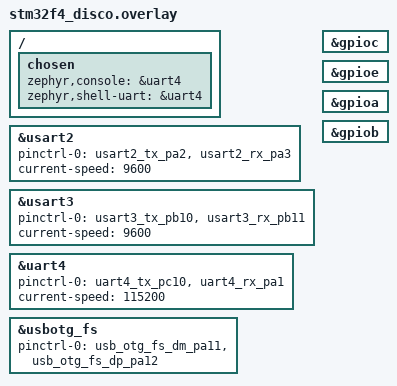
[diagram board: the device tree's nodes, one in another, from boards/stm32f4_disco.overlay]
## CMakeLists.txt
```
cmake_minimum_required(VERSION 3.20.0)

find_package(Zephyr REQUIRED HINTS $ENV{ZEPHYR_BASE})
project(usb_hid_proxy)

# Add source files
target_sources(app PRIVATE
    src/main.c
    src/drivers/ch375.c
    src/drivers/ch375_host.c
    src/drivers/ch375_uart.c
    src/hid/hid_parser.c
    src/hid/hid_mouse.c
    src/hid/hid_keyboard.c
    src/usb/composite_hid.c
    src/auto_gun_press.c
)

# Add include directories
target_include_directories(app PRIVATE
    ${CMAKE_CURRENT_SOURCE_DIR}/include
)

# Link against STM32 LL libraries for direct UART access
# These are needed for 9-bit UART configuration
zephyr_library_include_directories(
    ${ZEPHYR_BASE}/modules/hal/stm32/stm32cube/stm32f4xx/drivers/include
    ${ZEPHYR_BASE}/modules/hal/stm32/stm32cube/stm32f4xx/soc
)
```

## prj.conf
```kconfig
CONFIG_CONSOLE=y
CONFIG_UART_CONSOLE=y
CONFIG_GPIO=y
CONFIG_LOG=y
CONFIG_LOG_DEFAULT_LEVEL=3
```

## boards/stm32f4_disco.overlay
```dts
/ {
    chosen {
        zephyr,console = &uart4;
        zephyr,shell-uart = &uart4;
    };
};

/* Configure UARTs for CH375 */
&usart2 {
    pinctrl-0 = <&usart2_tx_pa2 &usart2_rx_pa3>;
    pinctrl-names = "default";
    current-speed = <9600>;
    status = "okay";
};

&usart3 {
    pinctrl-0 = <&usart3_tx_pb10 &usart3_rx_pb11>;
    pinctrl-names = "default";
    current-speed = <9600>;
    status = "okay";
};

/* Log UART */
&uart4 {
    pinctrl-0 = <&uart4_tx_pc10 &uart4_rx_pa1>;
    pinctrl-names = "default";
    current-speed = <115200>;
    status = "okay";
};

/* USB OTG FS for device mode */
&usbotg_fs {
    status = "okay";
    pinctrl-0 = <&usb_otg_fs_dm_pa11 &usb_otg_fs_dp_pa12>;
    pinctrl-names = "default";
};

/* GPIO ports */
&gpioc {
    status = "okay";
};

&gpioe {
    status = "okay";
};

&gpioa {
    status = "okay";
};

&gpiob {
    status = "okay";
};
```

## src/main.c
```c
/* Main application - Zephyr style with proper device tree usage */

#include <zephyr/kernel.h>
#include <zephyr/device.h>
#include <zephyr/drivers/gpio.h>
#include <zephyr/drivers/uart.h>
#include <zephyr/usb/usb_device.h>
#include <zephyr/usb/class/usb_hid.h>
#include <zephyr/logging/log.h>

#include "ch375/ch375.h"
#include "ch375/ch375_host.h"
#include "ch375/ch375_uart.h"
#include "hid/hid_mouse.h"
#include "hid/hid_keyboard.h"
#include "usb/composite_hid.h"
#include "auto_gun_press.h"

LOG_MODULE_REGISTER(main, LOG_LEVEL_INF);

#define CH375_MODULE_NUM 2

/* Device context structure */
typedef struct {
    const char *name;
    const struct device *uart_dev;
    struct gpio_dt_spec int_gpio;

    struct ch375_context *ch375_ctx;
    struct usb_device usbdev;
    struct usbhid_device hiddev;
    union {
        struct hid_mouse mouse;
        struct hid_keyboard keyboard;
    };

    uint8_t is_connected;
    uint8_t interface_num;
} device_input_t;

/* Global state */
static device_input_t s_arr_devin[CH375_MODULE_NUM];
static struct agp_context *s_agp_ctx;
static uint8_t s_enable_gun_press;
static uint8_t s_started_gun_press;

/* Forward declaration for composite HID send function (provided by your composite_hid module) */
int composite_hid_send_report(uint8_t iface_index, const uint8_t *report, size_t len);

/* Device initialization using device tree */
static int init_device_input_dt(device_input_t *devin,
                                const char *uart_label,
                                const struct device *uart_dev,
                                const struct gpio_dt_spec *int_gpio,
                                const char *dev_name,
                                uint8_t interface_num)
{
    int ret;

    devin->name = dev_name;
    devin->interface_num = interface_num;
    devin->int_gpio = *int_gpio;
    devin->uart_dev = uart_dev;

    if (!device_is_ready(devin->uart_dev)) {
        LOG_ERR("UART device %s not ready", uart_label);
        return -ENODEV;
    }

    LOG_INF("Found UART device: %s", uart_label);

    /* Initialize CH375 hardware */
    ret = ch375_hw_init(devin->name,
                       devin->uart_dev,
                       devin->int_gpio,
                       CH375_DEFAULT_BAUDRATE,
                       &devin->ch375_ctx);
    if (ret < 0) {
        LOG_ERR("Failed to init CH375 hardware: %d", ret);
        return ret;
    }

    /* Initialize CH375 in host mode */
    ret = ch375_host_init(devin->ch375_ctx, CH375_WORK_BAUDRATE);
    if (ret != CH375_HOST_SUCCESS) {
        LOG_ERR("Failed to initialize CH375 host: %d", ret);
        return -EIO;
    }

    /* Reconfigure UART for working baudrate */
    ret = ch375_hw_set_baudrate(devin->ch375_ctx, CH375_WORK_BAUDRATE);
    if (ret < 0) {
        LOG_ERR("Failed to set working baudrate: %d", ret);
        return ret;
    }

    LOG_INF("Initialized %s", devin->name);
    return 0;
}

/* Process mouse HID reports */
static int handle_mouse(struct hid_mouse *mouse, uint8_t interface_num)
{
    struct usbhid_device *hiddev = mouse->hid_dev;
    uint8_t *report_buf = NULL;
    int ret;
    uint32_t button_value;
    uint8_t fetch_success = 0;
    uint8_t need_send = 0;
    size_t report_len = hiddev->report_length;

    /* Fetch incoming report from host-side device. This updates the usbhid report buffer. */
    ret = hid_mouse_fetch_report(mouse);
    if (ret == USBHID_SUCCESS) {
        fetch_success = 1;
        need_send = 1;
    }

    /* Grab pointer to the report buffer (may be internal) */
    ret = usbhid_get_report_buffer(hiddev, &report_buf, NULL, USBHID_NOW);
    if (ret != USBHID_SUCCESS) {
        /* If no new report and nothing to send, skip */
        if (!need_send) {
            return 0;
        }
        /* fallback: still try to proceed if report_buf NULL */
    }

    /* Check left mouse button for auto gun press */
    hid_mouse_get_button(mouse, HID_MOUSE_BUTTON_LEFT, &button_value, USBHID_NOW);
    if (button_value) {
        if (!s_started_gun_press) {
            s_started_gun_press = 1;
            agp_restart(s_agp_ctx);
        }
    } else {
        s_started_gun_press = 0;
    }

    /* Apply auto gun press if enabled */
    if (s_enable_gun_press && s_started_gun_press) {
        struct agp_data data;
        ret = agp_get_data(s_agp_ctx, &data);
        if (ret == 0) {
            int32_t value;

            /* Add compensation to existing mouse movement */
            if (fetch_success && report_buf) {
                hid_mouse_get_orientation(mouse, HID_MOUSE_AXIS_X, &value, USBHID_NOW);
                data.x += value;
                hid_mouse_get_orientation(mouse, HID_MOUSE_AXIS_Y, &value, USBHID_NOW);
                data.y += value;
            }

            /* Write back orientation fields into the report buffer via hid_mouse helpers */
            hid_mouse_set_orientation(mouse, HID_MOUSE_AXIS_X, data.x, USBHID_NOW);
            hid_mouse_set_orientation(mouse, HID_MOUSE_AXIS_Y, data.y, USBHID_NOW);
            need_send = 1;
        }
    }

    if (need_send && report_buf) {
        /* Forward the report out via composite HID device.
           hid_device_send_report should send the payload for the interface index.
         */
        int cret = hid_device_send_report(interface_num, report_buf, report_len);
        if (cret != 0) {
            LOG_ERR("hid_device_send_report(iface=%d) failed: %d", interface_num, cret);
            return -EIO;
        }
    }

    return 0;
}

/* Process keyboard HID reports */
static int handle_keyboard(struct hid_keyboard *keyboard, uint8_t interface_num)
{
    struct usbhid_device *hiddev = keyboard->hid_dev;
    uint8_t *report_buf = NULL;
    int ret;
    uint32_t value;
    size_t report_len = hiddev->report_length;

    ret = hid_keyboard_fetch_report(keyboard);
    if (ret != USBHID_SUCCESS) {
        return ret;
    }

    ret = usbhid_get_report_buffer(hiddev, &report_buf, NULL, USBHID_NOW);
    if (ret != USBHID_SUCCESS || report_buf == NULL) {
        LOG_WRN("Keyboard: no report buffer available right now");
        return 0;
    }

    /* Check for control keys */
    hid_keyboard_get_key(keyboard, HID_KBD_NUMBER(1), &value, USBHID_NOW);
    if (value) {
        s_enable_gun_press = 1;
        LOG_INF("Auto gun press enabled");
    }

    hid_keyboard_get_key(keyboard, HID_KBD_NUMBER(2), &value, USBHID_NOW);
    if (value) {
        s_enable_gun_press = 0;
        LOG_INF("Auto gun press disabled");
    }

    /* Weapon selection */
    hid_keyboard_get_key(keyboard, HID_KBD_LETTER('k'), &value, USBHID_NOW);
    if (value) {
        agp_set_collect(s_agp_ctx, AGP_COLLECT_IDX_AK47);
        LOG_INF("Selected AK47 profile");
    }

    hid_keyboard_get_key(keyboard, HID_KBD_LETTER('m'), &value, USBHID_NOW);
    if (value) {
        agp_set_collect(s_agp_ctx, AGP_COLLECT_IDX_M4A4);
        LOG_INF("Selected M4A4 profile");
    }

    /* Coefficient adjustment */
    hid_keyboard_get_key(keyboard, HID_KBD_EQUAL, &value, USBHID_NOW);
    if (value) {
        agp_coefficient_change(s_agp_ctx, 1);
    }

    hid_keyboard_get_key(keyboard, HID_KBD_MINUS, &value, USBHID_NOW);
    if (value) {
        agp_coefficient_change(s_agp_ctx, 0);
    }

    /* Forward keyboard report to the composite device */
    if (report_buf) {
        int cret = hid_device_send_report(interface_num, report_buf, report_len);
        if (cret != 0) {
            LOG_ERR("hid_device_send_report(iface=%d) failed: %d", interface_num, cret);
            return -EIO;
        }
    }

    return 0;
}

/* Open device input (USB HID host side) */
static int open_device_in(device_input_t *devin)
{
    struct usb_device *udev = &devin->usbdev;
    struct usbhid_device *hiddev = &devin->hiddev;
    struct hid_mouse *mouse = &devin->mouse;
    struct hid_keyboard *keyboard = &devin->keyboard;
    int ret;

    LOG_INF("%s: Opening USB device...", devin->name);

    ret = ch375_host_udev_open(devin->ch375_ctx, udev);
    if (ret != CH375_HOST_SUCCESS) {
        LOG_ERR("%s: Failed to open USB device: %d", devin->name, ret);
        return -1;
    }

    LOG_INF("%s: USB device opened (VID:PID = %04X:%04X)",
           devin->name, udev->vid, udev->pid);

    /* Open USBHID device (interface 0) */
    ret = usbhid_open(udev, 0, hiddev);
    if (ret != USBHID_SUCCESS) {
        LOG_ERR("%s: Failed to open USBHID: %d", devin->name, ret);
        ch375_host_udev_close(udev);
        return -1;
    }

    LOG_INF("%s: USBHID opened (type: %s)",
           devin->name,
           hiddev->hid_type == USBHID_TYPE_MOUSE ? "Mouse" :
           hiddev->hid_type == USBHID_TYPE_KEYBOARD ? "Keyboard" : "Unknown");

    /* Open HID class device */
    if (hiddev->hid_type == USBHID_TYPE_MOUSE) {
        ret = hid_mouse_open(hiddev, mouse);
        if (ret != USBHID_SUCCESS) {
            LOG_ERR("%s: Failed to open mouse: %d", devin->name, ret);
            goto cleanup;
        }
        LOG_INF("%s: Mouse opened", devin->name);
    } else if (hiddev->hid_type == USBHID_TYPE_KEYBOARD) {
        ret = hid_keyboard_open(hiddev, keyboard);
        if (ret != USBHID_SUCCESS) {
            LOG_ERR("%s: Failed to open keyboard: %d", devin->name, ret);
            goto cleanup;
        }
        LOG_INF("%s: Keyboard opened", devin->name);
    } else {
        LOG_ERR("%s: Unsupported HID type: %d", devin->name, hiddev->hid_type);
        goto cleanup;
    }

    return 0;

cleanup:
    usbhid_close(hiddev);
    ch375_host_udev_close(udev);
    return -1;
}

/* Wait for all devices to connect */
static void wait_all_device_connect(void)
{
    uint8_t all_connected = 0;
    int ret;

    while (!all_connected) {
        all_connected = 1;

        for (int i = 0; i < CH375_MODULE_NUM; i++) {
            device_input_t *devin = &s_arr_devin[i];

            if (devin->is_connected) {
                continue;
            }

            ret = ch375_host_wait_device_connect(devin->ch375_ctx, 500);
            if (ret == CH375_HOST_SUCCESS) {
                LOG_INF("%s: Device connected", devin->name);
                devin->is_connected = 0;  /* Not fully enumerated yet */
            } else if (ret == CH375_HOST_ERROR) {
                LOG_ERR("%s: Error waiting for device", devin->name);
                all_connected = 0;
            } else {
                /* Timeout - keep waiting */
                all_connected = 0;
            }
        }

        if (!all_connected) {
            k_msleep(100);
        }
    }
}

/* Open all input devices */
static int open_all_device_in(void)
{
    int ret;

    for (int i = 0; i < CH375_MODULE_NUM; i++) {
        ret = open_device_in(&s_arr_devin[i]);
        if (ret < 0) {
            LOG_ERR("%s: Failed to enumerate", s_arr_devin[i].name);
            return ret;
        }
        s_arr_devin[i].is_connected = 1;
    }

    return 0;
}

/* Open device output (USB composite HID) */
static void open_device_out(void)
{
    int status;

    for (int i = 0; i < CH375_MODULE_NUM; i++) {
        device_input_t *devin = &s_arr_devin[i];
        struct usbhid_device *hiddev = &devin->hiddev;

        if (!devin->is_connected) {
            continue;
        }

        status = composite_hid_register_interface(i,
            hiddev->raw_hid_report_desc,
            hiddev->raw_hid_report_desc_len,
            8, 1);

        if (status != 0) {
            LOG_ERR("Failed to register HID interface %d", i);
        }
    }

    status = composite_hid_init();
    if (status != 0) {
        LOG_ERR("Failed to initialize composite HID");
    }
}

/* Main HID processing loop */
static void loop_handle_devices(void)
{
    int ret;

    while (1) {
        for (int i = 0; i < CH375_MODULE_NUM; i++) {
            device_input_t *devin = &s_arr_devin[i];

            if (!devin->is_connected) {
                continue;
            }

            if (devin->hiddev.hid_type == USBHID_TYPE_MOUSE) {
                ret = handle_mouse(&devin->mouse, devin->interface_num);
            } else if (devin->hiddev.hid_type == USBHID_TYPE_KEYBOARD) {
                ret = handle_keyboard(&devin->keyboard, devin->interface_num);
            } else {
                continue;
            }

            if (ret == USBHID_NO_DEV) {
                LOG_ERR("%s: Device disconnected", devin->name);
                return;  /* Exit loop to restart */
            }
        }

        k_msleep(1);  /* 1ms polling interval */
    }
}

/* Close all devices */
static void close_all_devices(void)
{
    for (int i = 0; i < CH375_MODULE_NUM; i++) {
        device_input_t *devin = &s_arr_devin[i];

        if (devin->hiddev.hid_type == USBHID_TYPE_MOUSE) {
            hid_mouse_close(&devin->mouse);
        } else if (devin->hiddev.hid_type == USBHID_TYPE_KEYBOARD) {
            hid_keyboard_close(&devin->keyboard);
        }

        usbhid_close(&devin->hiddev);
        ch375_host_udev_close(&devin->usbdev);

        devin->is_connected = 0;
    }

    composite_hid_cleanup();
}

int main(void)
{
    int ret;

    /* Define INT GPIO specs directly - PC13 and PC14 */
    static const struct gpio_dt_spec ch375a_int = {
        .port = DEVICE_DT_GET(DT_NODELABEL(gpioc)),
        .pin = 13,
        .dt_flags = GPIO_ACTIVE_LOW
    };

    static const struct gpio_dt_spec ch375b_int = {
        .port = DEVICE_DT_GET(DT_NODELABEL(gpioc)),
        .pin = 14,
        .dt_flags = GPIO_ACTIVE_LOW
    };

    LOG_INF("=================================");
    LOG_INF("USB HID Proxy Starting...");
    LOG_INF("=================================");

    /* Test GPIO access */
    const struct device *gpioc = DEVICE_DT_GET(DT_NODELABEL(gpioc));
    if (!device_is_ready(gpioc)) {
        LOG_ERR("GPIO C not ready!");
        return -1;
    }
    LOG_INF("GPIO C is ready");

    /* Get UART devices using DT macros */
    const struct device *uart2 = DEVICE_DT_GET(DT_NODELABEL(usart2));
    if (!device_is_ready(uart2)) {
        LOG_ERR("USART2 not ready");
        return -1;
    }
    LOG_INF("USART2 ready");

    const struct device *uart3 = DEVICE_DT_GET(DT_NODELABEL(usart3));
    if (!device_is_ready(uart3)) {
        LOG_ERR("USART3 not ready");
        return -1;
    }
    LOG_INF("USART3 ready");

    const struct device *uart4 = DEVICE_DT_GET(DT_NODELABEL(uart4));
    if (!device_is_ready(uart4)) {
        LOG_ERR("UART4 not ready");
        return -1;
    }
    LOG_INF("UART4 ready");

    LOG_INF("=================================");
    LOG_INF("Basic tests complete");
    LOG_INF("=================================");

    /* Initialize device inputs */
    ret = init_device_input_dt(&s_arr_devin[0], "USART2", uart2, &ch375a_int, "CH375A", 0);
    if (ret) {
        LOG_ERR("Failed to initialize CH375A");
        return ret;
    }

    ret = init_device_input_dt(&s_arr_devin[1], "USART3", uart3, &ch375b_int, "CH375B", 1);
    if (ret) {
        LOG_ERR("Failed to initialize CH375B");
        return ret;
    }

    /* Initialize AGP context */
    ret = agp_open(&s_agp_ctx);
    if (ret < 0) {
        LOG_ERR("Failed to open AGP context");
        return ret;
    }

    /* Main loop - wait for devices and process */
    while (1) {
        LOG_INF("=================================");
        LOG_INF("Waiting for USB devices...");
        LOG_INF("=================================");

        /* Wait for both devices to connect */
        wait_all_device_connect();

        LOG_INF("=================================");
        LOG_INF("Enumerating devices...");
        LOG_INF("=================================");

        /* Enumerate both devices */
        ret = open_all_device_in();
        if (ret < 0) {
            LOG_ERR("Failed to enumerate devices");
            k_msleep(1000);
            continue;
        }

        LOG_INF("=================================");
        LOG_INF("Initializing USB device output...");
        LOG_INF("=================================");

        /* Register composite HID interfaces (populates interfaces[]) */
        open_device_out();

        /* Initialize composite HID (configure endpoints) */
        if (composite_hid_init() != 0) {
            LOG_ERR("composite_hid_init failed");
        }

        /* Enable the USB device stack (this actually powers the USB device stack,
        * so the host (PC) will see the device) */
        int usb_rc = usb_enable(NULL);
        if (usb_rc != 0) {
            LOG_ERR("usb_enable failed: %d", usb_rc);
        } else {
            LOG_INF("USB device enabled");
        }

        LOG_INF("=================================");
        LOG_INF("Starting HID processing loop...");
        LOG_INF("=================================");

        /* Process HID reports */
        loop_handle_devices();

        /* If we get here, a device disconnected */
        LOG_WRN("Device disconnected, restarting...");

        /* Disable USB device */
        usb_disable();

        /* Close all devices */
        close_all_devices();

        k_msleep(1000);
    }

    return 0;
}
```

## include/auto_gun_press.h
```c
#ifndef AUTO_GUN_PRESS_H
#define AUTO_GUN_PRESS_H
#include <stdint.h>

#define DEFAULT_COEFFICIENT 2.5f
#define DEFAULT_SENSITIVE   1.4f
#define AGP_SPLIT_NUM   12

typedef enum AGPCollectIndex {
    AGP_COLLECT_IDX_NONE = 0,
    AGP_COLLECT_IDX_AK47 = 1,
    AGP_COLLECT_IDX_M4A4 = 2,
} AGPCollectIndex;

typedef struct AGPData {
    int32_t x;
    int32_t y;
} AGPData;

typedef struct AGPContext AGPContext;

int agp_coefficient_change(AGPContext *context, uint8_t is_add);
int agp_sensitive_change(AGPContext *context, uint8_t is_add);
int agp_restart(AGPContext *context);
int agp_get_data(AGPContext *context, AGPData *data);
int agp_set_collect(AGPContext *context, uint32_t index);
void agp_close(AGPContext *context);
int agp_open(AGPContext **context);

#endif /* AUTO_GUN_PRESS_H */
```

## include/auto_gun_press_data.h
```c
#ifndef AUTO_GUN_PRESS_DATA_H
#define AUTO_GUN_PRESS_DATA_H

#include "auto_gun_press.h"

float AGP_RAW_DATA_NONE[] = {
    0, 0, 1000,
};

float AGP_RAW_DATA_AK47[] = {
    0, 0, 30,
    -3.77885, -7.33026, 99,
    3.88382, -18.674, 99,
    -2.49497, -29.9552, 99,
    -1.05429, -31.9007, 99,
    12.3244, -33.1178, 99,
    8.45939, -27.7364, 99,
    13.1337, -19.8188, 99,
    -16.9038, -15.1133, 99,
    -42.0762, 5.02222, 99,
    -23.1968, -9.1423, 99,
    13.4584, -7.82848, 99,
    -16.283, -1.73109, 99,
    -26.8526, 9.52371, 99,
    -2.44215, -5.35626, 99,
    37.232, -8.02386, 99,
    23.2809, -5.40851, 99,
    14.3236, -5.75076, 99,
    26.6208, 2.82855, 99,
    34.9165, 8.60448, 99,
    -19.1055, -5.58987, 99,
    5.08387, 0.156464, 99,
    -8.60053, -5.91907, 99,
    -9.06119, -2.09341, 99,
    20.3148, 2.80682, 99,
    6.87328, -5.38808, 99,
    -21.3522, -0.609879, 99,
    -33.0195, 2.71869, 99,
    -47.1704, 21.1572, 99,
    -14.4156, -0.197525, 109,
};

float AGP_RAW_DATA_M4A4[] = {
    0,0,20,
    0,0,88,
    1.3436535,-15.8159,88,
    -4.98035,-16.096,88,
    5.17241,-23.2379,88,
    -7.64901,-26.6215,88,
    -4.35077,-23.4396,88,
    16.2926,-13.9699,88,
    10.0171,-16.122,88,
    24.4126,-5.73607,88,
    -6.9532,-8.03185,88,
    -17.891,-5.34038,88,
    -27.7995,-0.496811,88,
    -28.203,2.01843,88,
    -24.4919,8.56436,88,
    -0.139397,-3.24046,88,
    7.04116,-9.62352,88,
    -11.3982,0.672928,88,
    -12.562,6.20432,88,
    3.55202,-1.73409,88,
    31.0881,-5.4948,88,
    13.6174,-6.05292,88,
    28.1378,1.83047,88,
    7.74411,-1.42644,88,
    11.7364,-5.93803,88,
    -11.0829,-3.38919,88,
    5.83399,-0.696899,98,
    4.18425,1.05573,88,
    2.55716,-4.91539,88,
    5.49631,-3.339,98,
};

#endif /* AUTO_GUN_PRESS_DATA_H */
```

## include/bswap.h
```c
#ifndef BSWAP_H
#define BSWAP_H

#include <stdint.h>

static inline uint16_t bswap16(uint16_t x) {
    return (uint16_t)((x << 8) | (x >> 8));
}
static inline uint32_t bswap32(uint32_t x) {
    return ((x & 0x000000FFU) << 24) |
           ((x & 0x0000FF00U) << 8) |
           ((x & 0x00FF0000U) >> 8) |
           ((x & 0xFF000000U) >> 24);
}
static inline uint64_t bswap64(uint64_t x) {
    return ((uint64_t)bswap32((uint32_t)(x & 0xFFFFFFFFULL)) << 32) |
           (uint64_t)bswap32((uint32_t)(x >> 32));
}

/* assume little-endian host in most Zephyr boards; if you need big-endian set HOST_WORDS_BIGENDIAN */
#ifndef HOST_WORDS_BIGENDIAN
#define le16_to_cpu(x) (x)
#define le32_to_cpu(x) (x)
#define cpu_to_le16(x) (x)
#define cpu_to_le32(x) (x)
#else
#define le16_to_cpu(x) bswap16(x)
#define le32_to_cpu(x) bswap32(x)
#define cpu_to_le16(x) bswap16(x)
#define cpu_to_le32(x) bswap32(x)
#endif

#endif /* BSWAP_H */
```

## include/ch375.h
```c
#ifndef CH375_H
#define CH375_H

#include <stdint.h>
#include "ch375_interface.h"

/* CH375 status/return values and API prototypes.
 * This header was trimmed of any platform HAL includes so it can live in Zephyr.
 */

#define CH375_USB_MODE_NO_DETECT    0x04
#define CH375_USB_MODE_NO_SOF       0x05
#define CH375_USB_MODE_SOF          0x06
#define CH375_USB_MODE_RESET        0x07

#define CH375_USB_INT_SUCCESS       0x14
#define CH375_USB_INT_CONNECT       0x15
#define CH375_USB_INT_DISCONNECT    0x16
#define CH375_USB_INT_BUF_OVER      0x17
#define CH375_USB_INT_USB_READY     0x18

#define CH375_CMD_RET_SUCCESS 0x51
#define CH375_CMD_RET_FAILED 0x5F

#define CH375_PID2STATUS(x) ((x) | 0x20)

/**
  * @brief   USB packet identification PID
  */
#define	CH375_USB_PID_NULL 0x00
#define	CH375_USB_PID_SOF 0x05
#define	CH375_USB_PID_SETUP	0x0D
#define	CH375_USB_PID_IN 0x09
#define	CH375_USB_PID_OUT 0x01
#define	CH375_USB_PID_ACK 0x02
#define	CH375_USB_PID_NAK 0x0A
#define	CH375_USB_PID_STALL	0x0E
#define	CH375_USB_PID_DATA0	0x03
#define	CH375_USB_PID_DATA1	0x0B
#define	CH375_USB_PID_PRE 0x0C

/**
 * @brief 
 */
#define CH375_USB_DESC_TYPE_DEV_DESC    0x01
#define CH375_USB_DESC_TYPE_CONFIG_DESC 0x02

#define CH375_USB_SPEED_LOW  1
#define CH375_USB_SPEED_FULL 0

#define ch375_setRetry_TIMES_ZROE      0x00
#define ch375_setRetry_TIMES_2MS       0x01
#define ch375_setRetry_TIMES_INFINITY  0x02

/* public prototypes exposed by the CH375 core implementation (ch375.c) */
int ch375_setBaudrate(CH375_Context_t *context, uint32_t baudrate);
int ch375_queryInt(CH375_Context_t *context);
int ch375_waitInt(CH375_Context_t *context, uint32_t timeout);

int ch375_writeCmd(CH375_Context_t *context, uint8_t cmd);
int ch375_readData(CH375_Context_t *context, uint8_t *data);
int ch375_writeBlockData(CH375_Context_t *context, uint8_t *buf, uint8_t len);
int ch375_readBlockData(CH375_Context_t *context, uint8_t *buf, uint8_t len, uint8_t *actual_len);

int ch375_checkExist(CH375_Context_t *context);
int ch375_getVersion(CH375_Context_t *context, uint8_t *version);
int ch375_setUSBMode(CH375_Context_t *context, uint8_t mode);
int ch375_getStatus(CH375_Context_t *context, uint8_t *status);
int ch375_abortNAK(CH375_Context_t *context);

int ch375_testConnect(CH375_Context_t *context, uint8_t *connect_status);
int ch375_getDevSpeed(CH375_Context_t *context, uint8_t *speed);
int ch375_setDevSpeed(CH375_Context_t *context, uint8_t speed);
int ch375_setUSBAddr(CH375_Context_t *context, uint8_t addr);

int ch375_setRetry(CH375_Context_t *context, uint8_t times);
int ch375_sendToken(CH375_Context_t *context, uint8_t ep, uint8_t tog, uint8_t pid, uint8_t *status);

void *ch375_getPriv(CH375_Context_t *context);

int ch375_closeContext(CH375_Context_t *context);
int ch375_openContext(CH375_Context_t **context,
    func_write_cmd write_cmd,
    func_write_data write_data,
    func_read_data read_data,
    func_query_int query_int,
    void *priv);

#endif /* CH375_H */
```

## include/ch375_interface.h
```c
#ifndef CH375_INTERFACE_H
#define CH375_INTERFACE_H

#include <stdint.h>

typedef struct CH375_Context_t CH375_Context_t;

#define CH375_CMD(_x) ((uint16_t)((_x) | 0x0100))
#define CH375_DATA(_x) ((uint16_t)((_x) | 0x0000))

typedef int (*func_write_cmd)(CH375_Context_t *context, uint8_t cmd);
typedef int (*func_write_data)(CH375_Context_t *context, uint8_t data);
typedef int (*func_read_data)(CH375_Context_t *context, uint8_t *data);
/* return 0 -> no interrupt, non-zero -> interrupt */
typedef int (*func_query_int)(CH375_Context_t *context);

enum CH375_ERRNO{
    CH375_SUCCESS = 0,
    CH375_ERROR = -1,
    CH375_PARAM_INVALID = -2,
    ch375_writeCmd_FAILD = -3,
    ch375_readData_FAILD = -4,
    CH375_NO_EXIST = -5,
    CH375_TIMEOUT = -6,
    CH375_NOT_FOUND = -7,    // can't find ch375 board.
};

void *ch375_getPriv(CH375_Context_t *context);
int ch375_closeContext(CH375_Context_t *context);
int ch375_openContext(CH375_Context_t **context,
    func_write_cmd write_cmd,
    func_write_data write_data,
    func_read_data read_data,
    func_query_int query_int,
    void *priv);

#endif /* CH375_INTERFACE_H */
```

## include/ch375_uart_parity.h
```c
/* ch375_uart_parity.h - parity MARK/SPACE transport for CH375 on Zephyr
 *
 * Exposes the full struct so application code can declare static instances.
 *
 * NOTE: This implementation uses uart_configure() to toggle parity
 * between UART_CFG_PARITY_ODD (MARK approximation) and UART_CFG_PARITY_EVEN (SPACE approximation).
 */

#pragma once

#include <zephyr/kernel.h>
#include <zephyr/device.h>
#include <zephyr/drivers/uart.h>
#include <zephyr/sys/printk.h>
#include <zephyr/logging/log.h>
#include <stdint.h>
#include <string.h>

#ifdef __cplusplus
extern "C" {
#endif

struct ch375_parity_ctx {
    const struct device *uart_dev;
    struct k_mutex lock;
    uint32_t baud;
    uint32_t char_time_ms; /* estimated time to send one char including start/parity/stop */
    /* saved baseline uart configuration (we set this on open). */
    struct uart_config baseline_cfg;
    char dev_label[32];
};

int ch375_parity_open(struct ch375_parity_ctx *ctx, const char *uart_label, uint32_t baud);
void ch375_parity_close(struct ch375_parity_ctx *ctx);
int ch375_parity_send_cmd(struct ch375_parity_ctx *ctx, uint8_t cmd);   /* MARK */
int ch375_parity_send_data(struct ch375_parity_ctx *ctx, uint8_t data); /* SPACE */
int ch375_parity_read_byte_timeout(struct ch375_parity_ctx *ctx, uint8_t *out, uint32_t timeout_ms);

#ifdef __cplusplus
}
#endif
```

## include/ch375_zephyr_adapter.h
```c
#ifndef CH375_ZEPHYR_ADAPTER_H
#define CH375_ZEPHYR_ADAPTER_H

#include <stdint.h>
#include "ch375_interface.h"

/**
 * @brief Open CH375 on a Zephyr UART + INT GPIO
 *
 * @param uart_label   Zephyr device name for UART (e.g. "UART_2", "UART_3")
 * @param gpio_label   Zephyr device name for GPIO controller (e.g. "GPIOA")
 * @param int_pin      GPIO pin number for CH375 INT line
 * @param ctx_out      output pointer to CH375_Context_t* (allocated inside ch375_openContext)
 *
 * @return CH375_SUCCESS on success, other CH375_* error codes on failure
 */
int ch375_zephyr_open(const char *uart_label,
                      const char *gpio_label,
                      uint32_t int_pin,
                      CH375_Context_t **ctx_out);

/**
 * @brief Close CH375 context opened via ch375_zephyr_open
 *
 * @param ctx CH375_Context_t* (will be freed)
 */
int ch375_zephyr_close(CH375_Context_t *ctx);

#endif /* CH375_ZEPHYR_ADAPTER_H */
```

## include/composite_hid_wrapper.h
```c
#ifndef COMPOSITE_HID_WRAPPER_H
#define COMPOSITE_HID_WRAPPER_H

#include <stdint.h>

/**
 * Send a raw HID report to the composite HID interface 'interface_idx'.
 * Returns 0 on success; negative on error.
 *
 * Note: Must be called from thread context (not IRQ). The underlying function
 * will call USBD_LL_Transmit() on the ST USB Device stack.
 */
int composite_hid_send_report(uint8_t interface_idx, const uint8_t *report, uint16_t len);

#endif /* COMPOSITE_HID_WRAPPER_H */
```

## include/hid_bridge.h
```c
#ifndef _HID_BRIDGE_H_
#define _HID_BRIDGE_H_

void hid_bridge_start(void *p1, void *p2, void *p3);
static void stack_monitor_thread(void *p1, void *p2, void *p3);

#endif /* _HID_BRIDGE_H_ */
```

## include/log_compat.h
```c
#ifndef LOG_COMPAT_H
#define LOG_COMPAT_H

#include <zephyr/kernel.h>
#include <zephyr/sys/printk.h>
#include <stdint.h>
#include <stdarg.h>

/* Lightweight project-wide logging macros mapped to printk.
 * These are intentionally NOT using Zephyr LOG_MODULE_REGISTER/DECLARE to avoid
 * the multiple-definition problem when included in headers.
 *
 * If you later want full Zephyr logging features, you can refactor:
 * - put LOG_MODULE_REGISTER(app_log, ...) into exactly one .c
 * - add LOG_MODULE_DECLARE(app_log) at the top of each .c that uses LOG_*
 */

#define INFO(fmt, ...)  printk("[INFO] " fmt "\n", ##__VA_ARGS__)
#define ERROR(fmt, ...) printk("[ERROR] " fmt "\n", ##__VA_ARGS__)
#define WARN(fmt, ...)  printk("[WARN] " fmt "\n", ##__VA_ARGS__)
#ifdef ENABLE_DEBUG
#define DEBUG(fmt, ...) printk("[DEBUG] " fmt "\n", ##__VA_ARGS__)
#else
#define DEBUG(fmt, ...) do { } while (0)
#endif

/* Backwards compatible functions used in legacy code */
void printf2(char *fmt, ...);
void hex_dump(uint8_t *buf, int len);

#endif /* LOG_COMPAT_H */
```

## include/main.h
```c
#ifndef __MAIN_H
#define __MAIN_H

#ifdef __cplusplus
extern "C" {
#endif

#define CUSTOM_HID_EPIN_SIZE        0x08U
#define CUSTOM_HID_EPOUT_SIZE       0x04U

/* Exported functions prototypes ---------------------------------------------*/
void Error_Handler(void);

/* Private defines -----------------------------------------------------------*/
#define user_btn_Pin GPIO_PIN_0
#define user_btn_GPIO_Port GPIOA

#define CH375A_INT_PIN GPIO_PIN_14
#define CH375A_INT_PORT GPIOE
#define CH375B_INT_PIN GPIO_PIN_15
#define CH375B_INT_PORT GPIOE

#define green_led_Pin GPIO_PIN_12
#define green_led_GPIO_Port GPIOD
#define orange_led_Pin GPIO_PIN_13
#define orange_led_GPIO_Port GPIOD
#define red_led_Pin GPIO_PIN_14
#define red_led_GPIO_Port GPIOD
#define blue_led_Pin GPIO_PIN_15
#define blue_led_GPIO_Port GPIOD

/* USER CODE BEGIN Private defines */
// CH375 CONFIG
#define CH375_WORK_BAUDRATE     115200
#define CH375_DEFAULT_BAUDRATE  9600
#define CH375_MODULE_NUM        2
/* USER CODE END Private defines */

#ifdef __cplusplus
}
#endif

#endif /* __MAIN_H */
```

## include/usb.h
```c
/* include/usb.h -- USB descriptor & constants used by ch375 host code */

#ifndef USB_H
#define USB_H

#include <stdint.h>

#define	USB_PID_NULL	0x00
#define	USB_PID_SOF		0x05
#define	USB_PID_SETUP	0x0D
#define	USB_PID_IN		0x09
#define	USB_PID_OUT		0x01
#define	USB_PID_ACK		0x02
#define	USB_PID_NAK		0x0A
#define	USB_PID_STALL	0x0E
#define	USB_PID_DATA0	0x03
#define	USB_PID_DATA1	0x0B
#define	USB_PID_PRE		0x0C

/* Device and/or Interface Class codes */
enum USB_ClassCode_e {
	USB_CLASS_PER_INTERFACE 		= 0x00,
	USB_CLASS_AUDIO 				= 0x01,
	USB_CLASS_COMM 					= 0x02,
	USB_CLASS_HID 					= 0x03,
	USB_CLASS_PHYSICAL 				= 0x05,
	USB_CLASS_IMAGE 				= 0x06,
	USB_CLASS_PTP 					= 0x06, 	//legacy
	USB_CLASS_PRINTER 				= 0x07,
	USB_CLASS_MASS_STORAGE 			= 0x08,
	USB_CLASS_HUB 					= 0x09,
	USB_CLASS_DATA 					= 0x0a,
	USB_CLASS_SMART_CARD 			= 0x0b,
	USB_CLASS_CONTENT_SECURITY 		= 0x0d,
	USB_CLASS_VIDEO 				= 0x0e,
	USB_CLASS_PERSONAL_HEALTHCARE 	= 0x0f,
	USB_CLASS_DIAGNOSTIC_DEVICE 	= 0xdc,
	USB_CLASS_WIRELESS 				= 0xe0,
	USB_CLASS_MISCELLANEOUS 		= 0xef,
	USB_CLASS_APPLICATION 			= 0xfe,
	USB_CLASS_VENDOR_SPEC 			= 0xff
};

/* Descriptor types as defined by the USB specification. */
enum DescriptorType_e {
	USB_DT_DEVICE 					= 0x01,
	USB_DT_CONFIG 					= 0x02,
	USB_DT_STRING 					= 0x03,
	USB_DT_INTERFACE 				= 0x04,
	USB_DT_ENDPOINT 				= 0x05,
	USB_DT_BOS 						= 0x0f,
	USB_DT_DEVICE_CAPABILITY 		= 0x10,
	USB_DT_HID 						= 0x21,
	USB_DT_REPORT 					= 0x22,
	USB_DT_PHYSICAL 				= 0x23,
	USB_DT_HUB 						= 0x29,
	USB_DT_SUPERSPEED_HUB 			= 0x2a,
	USB_DT_SS_ENDPOINT_COMPANION 	= 0x30
};

enum USB_EndpointTransferType_e {
	USB_ENDPOINT_TRANSFER_TYPE_CONTROL 		= 0x0,
	USB_ENDPOINT_TRANSFER_TYPE_ISOCHRONOUS 	= 0x1,
	USB_ENDPOINT_TRANSFER_TYPE_BULK 		= 0x2,
	USB_ENDPOINT_TRANSFER_TYPE_INTERRUPT 	= 0x3
};

/* Standard requests (table 9-5 of USB 3.0 specs) */
enum USB_StandardRequest_e {
	USB_REQUEST_GET_STATUS 			= 0x00,
	USB_REQUEST_CLEAR_FEATURE 		= 0x01,
	USB_REQUEST_SET_FEATURE 		= 0x03,
	USB_REQUEST_SET_ADDRESS 		= 0x05,
	USB_REQUEST_GET_DESCRIPTOR 		= 0x06,
	USB_REQUEST_SET_DESCRIPTOR 		= 0x07,
	USB_REQUEST_GET_CONFIGURATION 	= 0x08,
	USB_REQUEST_SET_CONFIGURATION 	= 0x09,
	USB_REQUEST_GET_INTERFACE 		= 0x0a,
	USB_REQUEST_SET_INTERFACE 		= 0x0b,
	USB_REQUEST_SYNCH_FRAME 		= 0x0c,
	USB_REQUEST_SET_SEL 			= 0x30,
	USB_SET_ISOCH_DELAY 			= 0x31
};

/* Endpoint direction (bit 7 of endpoint address) */
enum USB_EndpointDirection_e {
	USB_ENDPOINT_OUT 	= 0x00,
	USB_ENDPOINT_IN 	= 0x80
};

/* bmRequestType: D6~5 */
enum USB_RequestType_e {
	USB_REQUEST_TYPE_STANDARD 	= (0x00 << 5),
	USB_REQUEST_TYPE_CLASS 		= (0x01 << 5),
	USB_REQUEST_TYPE_VENDOR 	= (0x02 << 5),
	USB_REQUEST_TYPE_RESERVED 	= (0x03 << 5)
};

/* bmRequestType: D4~0 */
enum USB_RequestRecipient_e {
	USB_RECIPIENT_DEVICE 		= 0x00,
	USB_RECIPIENT_INTERFACE 	= 0x01,
	USB_RECIPIENT_ENDPOINT 		= 0x02,
	USB_RECIPIENT_OTHER 		= 0x03
};

#define DEVICE_DESC_LEN 0x12
#define CONTROL_SETUP_SIZE sizeof(USB_ControlSetup_t)

#pragma pack(push, 1)
typedef struct USB_ControlSetup_t {
    uint8_t bmRequestType;
    uint8_t bRequest;
    uint16_t wValue;
    uint16_t wIndex;
    uint16_t wLength;
} USB_ControlSetup_t;

typedef struct USB_DeviceDescriptor_t {
	uint8_t  bLength;
	uint8_t  bDescriptorType;
	uint16_t bcdUSB;
	uint8_t  bDeviceClass;
	uint8_t  bDeviceSubClass;
	uint8_t  bDeviceProtocol;
	uint8_t  bMaxPacketSize0;
	uint16_t idVendor;
	uint16_t idProduct;
	uint16_t bcdDevice;
	uint8_t  iManufacturer;
	uint8_t  iProduct;
	uint8_t  iSerialNumber;
	uint8_t  bNumConfigurations;
} USB_DeviceDescriptor_t;

typedef struct USB_Descriptor_t {
    uint8_t bLength;
    uint8_t bDesriptorType;
} USB_Descriptor_t;

typedef struct USB_HID_Descriptor_t_t {
	uint8_t bLength;
	uint8_t bDescriptorType;
	uint16_t bcdHID;
	uint8_t bCountryCode;
	uint8_t bNumDescriptors;
	uint8_t bClassDescriptorType_e;
	uint16_t wClassDescriptorLength;
} USB_HID_Descriptor_t_t;

typedef struct USB_EndpointDescriptor_t {
	uint8_t  bLength;
	uint8_t  bDescriptorType;
	uint8_t  bEndpointAddress;
	uint8_t  bmAttributes;
	uint16_t wMaxPacketSize;
	uint8_t  bInterval;
} USB_EndpointDescriptor_t;

typedef struct USB_InterfaceDescriptor_t {
	uint8_t  bLength;
	uint8_t  bDescriptorType;
	uint8_t  bInterfaceNumber;
	uint8_t  bAlternateSetting;
	uint8_t  bNumEndpoints;
	uint8_t  bInterfaceClass;
	uint8_t  bInterfaceSubClass;
	uint8_t  bInterfaceProtocol;
	uint8_t  iInterface;
} USB_InterfaceDescriptor_t;

typedef struct USB_ConfigDescriptor_t {
	uint8_t  bLength;
	uint8_t  bDescriptorType;
	uint16_t wTotalLength;
	uint8_t  bNumInterfaces;
	uint8_t  bConfigurationValue;
	uint8_t  iConfiguration;
	uint8_t  bmAttributes;
	uint8_t  MaxPower;
} USB_ConfigDescriptor_t;
#pragma pack(pop)

#endif /* USB_H */
```
